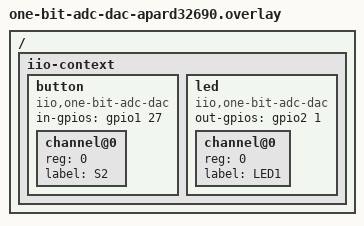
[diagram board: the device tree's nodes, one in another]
/*
 * Copyright (c) 2026 Analog Devices, Inc.
 *
 * SPDX-License-Identifier: MIT
 */

#include <zephyr/dt-bindings/gpio/gpio.h>

/ {
	iio-context {
		button {
			compatible = "iio,one-bit-adc-dac";
			#address-cells = <1>;
			#size-cells = <0>;

			in-gpios = <&gpio1 27 (GPIO_PULL_DOWN | GPIO_ACTIVE_HIGH)>;

			channel@0 {
				reg = <0>;
				label = "S2";
			};
		};

		led {
			compatible = "iio,one-bit-adc-dac";
			#address-cells = <1>;
			#size-cells = <0>;

			out-gpios = <&gpio2 1 GPIO_ACTIVE_HIGH>;

			channel@0 {
				reg = <0>;
				label = "LED1";
			};
		};
	};
};
